# UPD70F3508 register map
Vendor: Renesas; Series: V850E2/Px4; File version: 1.0
CPU: other r0p0, little endian, no MPU, FPU, 4 interrupt priority bits
Registers are 8-bit, read-write, reset 0x0 unless marked. A register's access mark holds for its fields unless they carry their own. Offsets are from the block's base; [hi:lo] are bit positions.

## PIC0_SST — Peripheral Interconnection Controller 0 — Simultaneous Start Trigger register
Base 0xFFFFDB04
0x00 PIC0SST wo — Simultaneous start trigger control register — write 1 to SYNCTRG to generate simultaneous start pulse
  [0] SYNCTRG — Generate simultaneous start trigger (write 1 = output 1-PCLK-wide pulse; always reads 0)

## CSIH0_B1 — Queue-Equipped Three-Line Serial Interface H 0, Bank 1 (memory/Tx/Rx/status registers at base1)
Base 0xFFFFE000
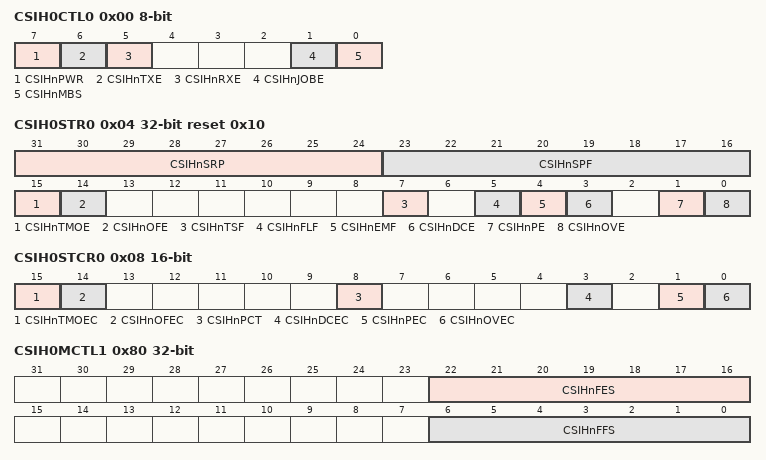
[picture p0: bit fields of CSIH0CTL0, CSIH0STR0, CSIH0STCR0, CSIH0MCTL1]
0x00 CSIH0CTL0 — CSIHn Control Register 0 — operation clock, Tx/Rx enable, memory bypass
  [7] CSIHnPWR — Operation clock control (0=stop, 1=provide)
  [6] CSIHnTXE — Transmission enable
  [5] CSIHnRXE — Reception enable
  [1] CSIHnJOBE — Job abort at end of current job
  [0] CSIHnMBS — Memory bypass (0=memory mode, 1=direct access mode)
0x04 CSIH0STR0 32-bit ro reset 0x10 — CSIHn Status Register 0 — FIFO pointers, error flags, transfer status
  [31:24] CSIHnSRP — Received words in FIFO [7:0] (FIFO mode only)
  [23:16] CSIHnSPF — Untransmitted data count in FIFO [7:0] (FIFO mode only)
  [15] CSIHnTMOE — Time-out error flag
  [14] CSIHnOFE — Overflow error flag
  [7] CSIHnTSF — Transfer status flag (0=idle, 1=active)
  [5] CSIHnFLF — FIFO full flag
  [4] CSIHnEMF — FIFO empty flag
  [3] CSIHnDCE — Data consistency check error flag
  [1] CSIHnPE — Parity error flag
  [0] CSIHnOVE — Overrun error flag
0x08 CSIH0STCR0 16-bit wo — CSIHn Status Clear Register 0 — clears STR0 flags; always reads as 0x0000
  [15] CSIHnTMOEC — Clear time-out error flag (STR0.CSIHnTMOE)
  [14] CSIHnOFEC — Clear overflow error flag (STR0.CSIHnOFE)
  [8] CSIHnPCT — FIFO pointer clear command
  [3] CSIHnDCEC — Clear data consistency error flag (STR0.CSIHnDCE)
  [1] CSIHnPEC — Clear parity error flag (STR0.CSIHnPE)
  [0] CSIHnOVEC — Clear overrun error flag (STR0.CSIHnOVE)
0x80 CSIH0MCTL1 32-bit — CSIHn Memory Control Register 1 — FIFO interrupt threshold levels
  [22:16] CSIHnFES — Tx FIFO empty interrupt threshold [6:0] — CSIHnTIC generated when SPF reaches this value
  [6:0] CSIHnFFS — Rx FIFO full interrupt threshold [6:0] — CSIHnTIR generated when (128-SRP) equals this
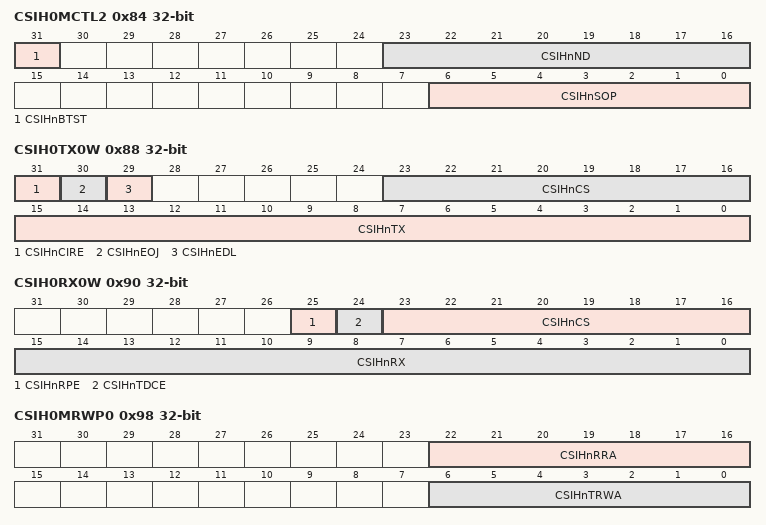
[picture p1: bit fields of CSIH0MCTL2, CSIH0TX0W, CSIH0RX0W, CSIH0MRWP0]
0x84 CSIH0MCTL2 32-bit — CSIHn Memory Control Register 2 — buffer transfer start, data count, send pointer
  [31] CSIHnBTST — Buffer transfer start trigger (write 1; always reads 0)
  [23:16] CSIHnND — Number of data for double-buffer/Tx-only-buffer mode [7:0]
  [6:0] CSIHnSOP — Send pointer for Tx buffer [6:0]
0x88 CSIH0TX0W 32-bit — CSIHn Transmission Register 0 for Word Access — Tx data + control flags + chip-select
  [31] CSIHnCIRE — Communication interrupt request enable for this frame
  [30] CSIHnEOJ — End-of-job marker for this frame
  [29] CSIHnEDL — Extended data length for this frame
  [23:16] CSIHnCS — Chip-select activation bitmap [7:0] (0=activated, 1=deactivated)
  [15:0] CSIHnTX — Transmission data [15:0]
0x8C CSIH0TX0H 16-bit — CSIHn Transmission Register 0 for Half Word Access — same as TX0W[15:0]
  [15:0] CSIHnTX — Transmission data [15:0]
0x90 CSIH0RX0W 32-bit ro — CSIHn Reception Register 0 for Word Access — received data + parity/consistency error flags + CS indicator
  [25] CSIHnRPE — Reception parity error on this frame
  [24] CSIHnTDCE — Transmission data consistency error on this frame
  [23:16] CSIHnCS — Chip-select active bitmap for this frame [7:0]
  [15:0] CSIHnRX — Received data [15:0]
0x94 CSIH0RX0H 16-bit ro — CSIHn Reception Register 0 for Half Word Access — same as RX0W[15:0]
  [15:0] CSIHnRX — Received data [15:0]
0x98 CSIH0MRWP0 32-bit — CSIHn Memory Read/Write Pointer Register 0 — Rx and Tx buffer pointers
  [22:16] CSIHnRRA — Rx buffer read pointer [6:0]
  [6:0] CSIHnTRWA — Tx buffer read/write pointer [6:0]
